# MK22FA12 register map
Vendor: Freescale Semiconductor, Inc.; Series: Kinetis_K; File version: 1.6
CPU: CM4 r0p1, little endian, no MPU, FPU, VTOR, 4 interrupt priority bits
Registers are 32-bit, read-write, reset 0x0 unless marked. A register's access mark holds for its fields unless they carry their own. Offsets are from the block's base; [hi:lo] are bit positions; {n}, {i} and the like mark numbered series; 'fields as' and 'values as' point back to an identical list.

## FMC — Flash Memory Controller
Base 0x4001F000; register names take the prefix FMC_
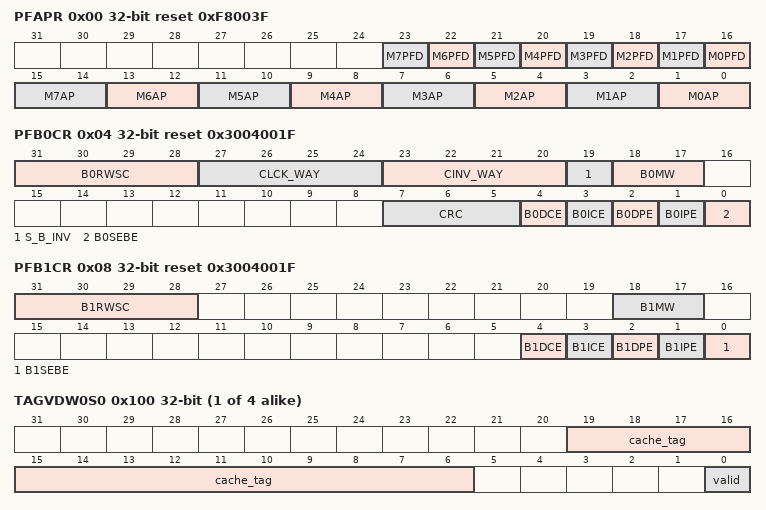
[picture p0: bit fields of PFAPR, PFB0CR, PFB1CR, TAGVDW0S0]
0x00 PFAPR reset 0xF8003F — Flash Access Protection Register
  [n+16] M{n}PFD (n=0..7) — Master {n} Prefetch Disable
    0=Prefetching for this master is enabled; 1=Prefetching for this master is disabled
  [2n+1:2n] M{n}AP (n=0..7) — Master {n} Access Protection
    0=No access may be performed by this master; 1=Only read accesses may be performed by this master; 2=Only write accesses may be performed by this master; 3=Both read and write accesses may be performed by this master
0x04 PFB0CR reset 0x3004001F — Flash Bank 0 Control Register
  [31:28] B0RWSC ro — Bank 0 Read Wait State Control
  [27:24] CLCK_WAY — Cache Lock Way x
    0=Cache way is unlocked and may be displaced; 1=Cache way is locked and its contents are not displaced
  [23:20] CINV_WAY wo — Cache Invalidate Way x
    0=No cache way invalidation for the corresponding cache; 1=Invalidate cache way for the corresponding cache: clear the tag, data, and vld bits of ways selected
  [19] S_B_INV wo — Invalidate Prefetch Speculation Buffer
    0=Speculation buffer and single entry buffer are not affected; 1=Invalidate (clear) speculation buffer and single entry buffer
  [18:17] B0MW ro — Bank 0 Memory Width
    0=32 bits; 1=64 bits; 2=128 bits
  [7:5] CRC — Cache Replacement Control
    0=LRU replacement algorithm per set across all four ways; 2=Independent LRU with ways [0-1] for ifetches, [2-3] for data; 3=Independent LRU with ways [0-2] for ifetches, [3] for data
  [4] B0DCE — Bank 0 Data Cache Enable
    0=Do not cache data references; 1=Cache data references
  [3] B0ICE — Bank 0 Instruction Cache Enable
    0=Do not cache instruction fetches; 1=Cache instruction fetches
  [2] B0DPE — Bank 0 Data Prefetch Enable
    0=Do not prefetch in response to data references; 1=Enable prefetches in response to data references
  [1] B0IPE — Bank 0 Instruction Prefetch Enable
    0=Do not prefetch in response to instruction fetches; 1=Enable prefetches in response to instruction fetches
  [0] B0SEBE — Bank 0 Single Entry Buffer Enable
    0=Single entry buffer is disabled; 1=Single entry buffer is enabled
0x08 PFB1CR reset 0x3004001F — Flash Bank 1 Control Register
  [31:28] B1RWSC ro — Bank 1 Read Wait State Control
  [18:17] B1MW ro — Bank 1 Memory Width
    0=32 bits; 1=64 bits; 2=128 bits
  [4] B1DCE — Bank 1 Data Cache Enable
    0=Do not cache data references; 1=Cache data references
  [3] B1ICE — Bank 1 Instruction Cache Enable
    values as PFB0CR.B0ICE
  [2] B1DPE — Bank 1 Data Prefetch Enable
    values as PFB0CR.B0DPE
  [1] B1IPE — Bank 1 Instruction Prefetch Enable
    values as PFB0CR.B0IPE
  [0] B1SEBE — Bank 1 Single Entry Buffer Enable
    values as PFB0CR.B0SEBE
{0x100+4i} TAGVDW0S{i} (i=0..3) — Cache Tag Storage
  [19:6] cache_tag — 14-bit tag for cache entry
  [0] valid — 1-bit valid for cache entry
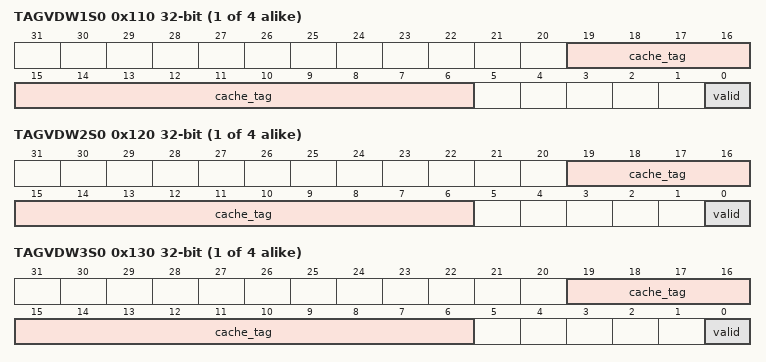
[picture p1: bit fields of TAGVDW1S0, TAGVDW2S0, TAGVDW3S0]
{0x110+4i} TAGVDW1S{i} (i=0..3) — Cache Tag Storage
  fields as TAGVDW0S0
{0x120+4i} TAGVDW2S{i} (i=0..3) — Cache Tag Storage
  fields as TAGVDW0S0
{0x130+4i} TAGVDW3S{i} (i=0..3) — Cache Tag Storage
  fields as TAGVDW0S0
{0x200+0x10*i} DATAW0S{i}UM (i=0..3) — Cache Data Storage (uppermost word)
  [31:0] data — Bits [127:96] of data entry
{0x204+0x10*i} DATAW0S{i}MU (i=0..3) — Cache Data Storage (mid-upper word)
  [31:0] data — Bits [95:64] of data entry
{0x208+0x10*i} DATAW0S{i}ML (i=0..3) — Cache Data Storage (mid-lower word)
  [31:0] data — Bits [63:32] of data entry
{0x20C+0x10*i} DATAW0S{i}LM (i=0..3) — Cache Data Storage (lowermost word)
  [31:0] data — Bits [31:0] of data entry
{0x240+0x10*i} DATAW1S{i}UM (i=0..3) — Cache Data Storage (uppermost word)
  [31:0] data — Bits [127:96] of data entry
{0x244+0x10*i} DATAW1S{i}MU (i=0..3) — Cache Data Storage (mid-upper word)
  [31:0] data — Bits [95:64] of data entry
{0x248+0x10*i} DATAW1S{i}ML (i=0..3) — Cache Data Storage (mid-lower word)
  [31:0] data — Bits [63:32] of data entry
{0x24C+0x10*i} DATAW1S{i}LM (i=0..3) — Cache Data Storage (lowermost word)
  [31:0] data — Bits [31:0] of data entry
{0x280+0x10*i} DATAW2S{i}UM (i=0..3) — Cache Data Storage (uppermost word)
  [31:0] data — Bits [127:96] of data entry
{0x284+0x10*i} DATAW2S{i}MU (i=0..3) — Cache Data Storage (mid-upper word)
  [31:0] data — Bits [95:64] of data entry
{0x288+0x10*i} DATAW2S{i}ML (i=0..3) — Cache Data Storage (mid-lower word)
  [31:0] data — Bits [63:32] of data entry
{0x28C+0x10*i} DATAW2S{i}LM (i=0..3) — Cache Data Storage (lowermost word)
  [31:0] data — Bits [31:0] of data entry
{0x2C0+0x10*i} DATAW3S{i}UM (i=0..3) — Cache Data Storage (uppermost word)
  [31:0] data — Bits [127:96] of data entry
{0x2C4+0x10*i} DATAW3S{i}MU (i=0..3) — Cache Data Storage (mid-upper word)
  [31:0] data — Bits [95:64] of data entry
{0x2C8+0x10*i} DATAW3S{i}ML (i=0..3) — Cache Data Storage (mid-lower word)
  [31:0] data — Bits [63:32] of data entry
{0x2CC+0x10*i} DATAW3S{i}LM (i=0..3) — Cache Data Storage (lowermost word)
  [31:0] data — Bits [31:0] of data entry
